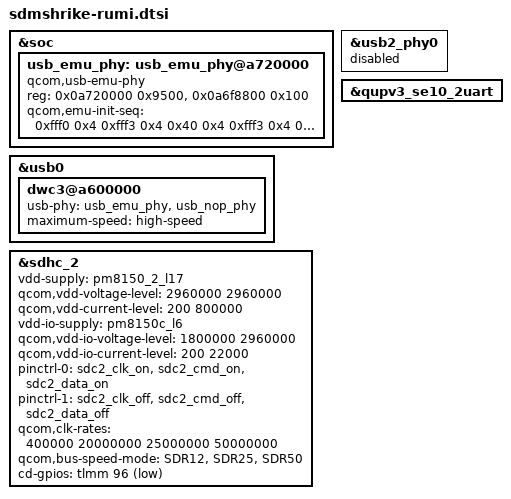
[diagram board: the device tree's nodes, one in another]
/* Copyright (c) 2018, The Linux Foundation. All rights reserved.
 *
 * This program is free software; you can redistribute it and/or modify
 * it under the terms of the GNU General Public License version 2 and
 * only version 2 as published by the Free Software Foundation.
 *
 * This program is distributed in the hope that it will be useful,
 * but WITHOUT ANY WARRANTY; without even the implied warranty of
 * MERCHANTABILITY or FITNESS FOR A PARTICULAR PURPOSE.  See the
 * GNU General Public License for more details.
 */

#include "sdmshrike-pmic-overlay.dtsi"

&soc {
	usb_emu_phy: usb_emu_phy@a720000 {
		compatible = "qcom,usb-emu-phy";
		reg = <0x0a720000 0x9500>,
		      <0x0a6f8800 0x100>;
		reg-names = "base", "qcratch_base";

		qcom,emu-init-seq = <0xfff0 0x4
				     0xfff3 0x4
				     0x40 0x4
				     0xfff3 0x4
				     0xfff0 0x4
				     0x100000 0x20
				     0x0 0x20
				     0x1a0 0x20
				     0x100000 0x3c
				     0x0 0x3c
				     0x10060 0x3c
				     0x0 0x4>;
	};
};

&usb0 {
	dwc3@a600000 {
		usb-phy = <&usb_emu_phy>, <&usb_nop_phy>;
		maximum-speed = "high-speed";
	};
};

&usb2_phy0 {
	status = "disabled";
};

&sdhc_2 {
	vdd-supply = <&pm8150_2_l17>;
	qcom,vdd-voltage-level = <2960000 2960000>;
	qcom,vdd-current-level = <200 800000>;

	vdd-io-supply = <&pm8150c_l6>;
	qcom,vdd-io-voltage-level = <1800000 2960000>;
	qcom,vdd-io-current-level = <200 22000>;

	pinctrl-names = "active", "sleep";
	pinctrl-0 = <&sdc2_clk_on  &sdc2_cmd_on &sdc2_data_on>;
	pinctrl-1 = <&sdc2_clk_off &sdc2_cmd_off &sdc2_data_off>;

	qcom,clk-rates = <400000 20000000 25000000 50000000>;
	qcom,bus-speed-mode = "SDR12", "SDR25", "SDR50";

	/delete-property/qcom,devfreq,freq-table;

	cd-gpios = <&tlmm 96 0x1>;

	status = "ok";
};

&qupv3_se10_2uart {
	status = "ok";
};
